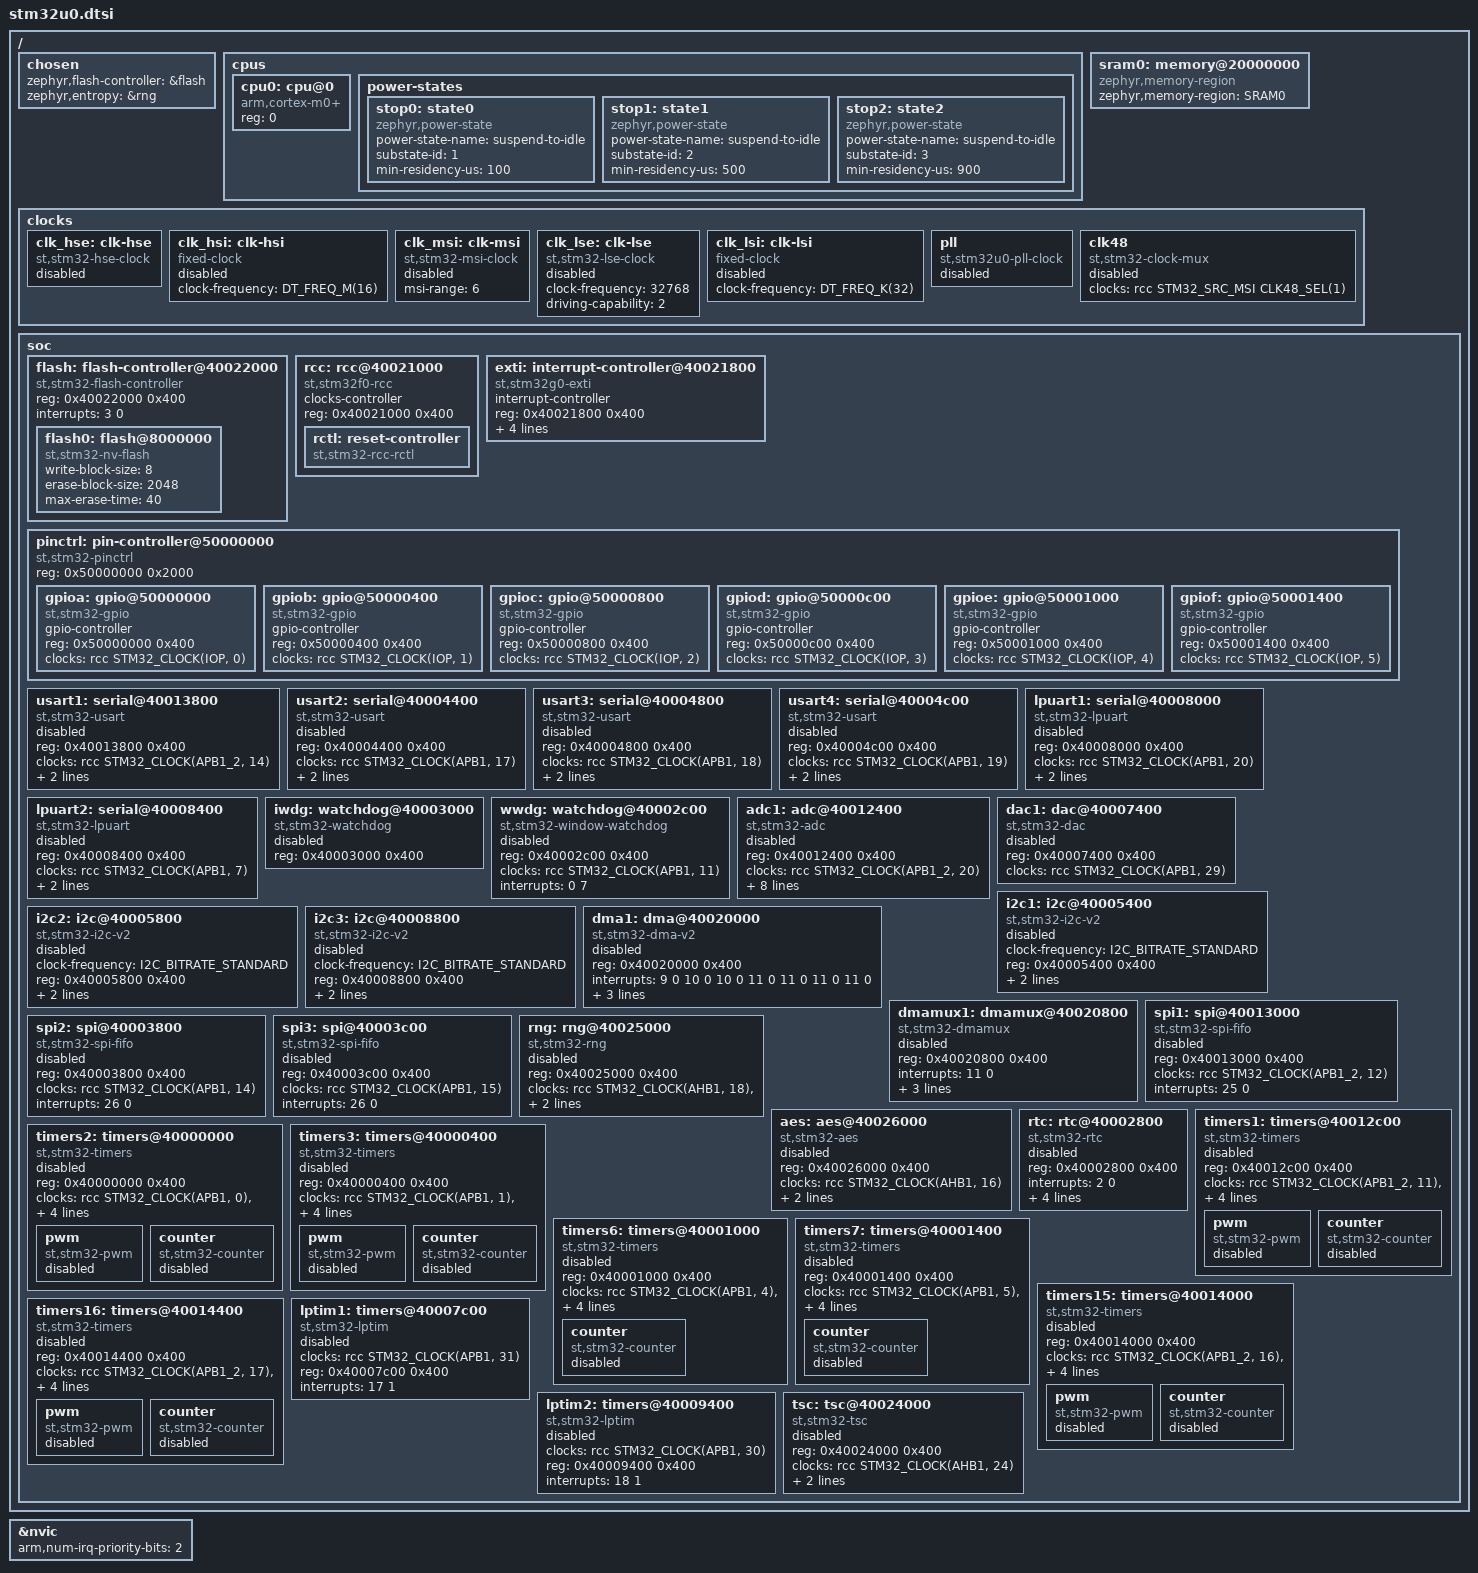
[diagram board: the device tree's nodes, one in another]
/*
 * Copyright (c) 2024 STMicroelectronics
 *
 * SPDX-License-Identifier: Apache-2.0
 */

#include <arm/armv6-m.dtsi>
#include <zephyr/dt-bindings/clock/stm32u0_clock.h>
#include <zephyr/dt-bindings/gpio/gpio.h>
#include <zephyr/dt-bindings/adc/adc.h>
#include <zephyr/dt-bindings/adc/stm32l4_adc.h>
#include <zephyr/dt-bindings/pwm/pwm.h>
#include <zephyr/dt-bindings/pwm/stm32_pwm.h>
#include <zephyr/dt-bindings/dma/stm32_dma.h>
#include <zephyr/dt-bindings/i2c/i2c.h>
#include <zephyr/dt-bindings/reset/stm32u0_reset.h>
#include <freq.h>
#include <mem.h>

/ {
	chosen {
		zephyr,flash-controller = &flash;
		zephyr,entropy = &rng;
	};

	cpus {
		#address-cells = <1>;
		#size-cells = <0>;

		cpu0: cpu@0 {
			device_type = "cpu";
			compatible = "arm,cortex-m0+";
			reg = <0>;
			#address-cells = <1>;
			#size-cells = <1>;
		};

		power-states {
			stop0: state0 {
				compatible = "zephyr,power-state";
				power-state-name = "suspend-to-idle";
				substate-id = <1>;
				min-residency-us = <100>;
			};

			stop1: state1 {
				compatible = "zephyr,power-state";
				power-state-name = "suspend-to-idle";
				substate-id = <2>;
				min-residency-us = <500>;
			};

			stop2: state2 {
				compatible = "zephyr,power-state";
				power-state-name = "suspend-to-idle";
				substate-id = <3>;
				min-residency-us = <900>;
			};
		};
	};

	sram0: memory@20000000 {
		compatible = "zephyr,memory-region", "mmio-sram";
		zephyr,memory-region = "SRAM0";
	};

	clocks {
		clk_hse: clk-hse {
			#clock-cells = <0>;
			compatible = "st,stm32-hse-clock";
			status = "disabled";
		};

		clk_hsi: clk-hsi {
			#clock-cells = <0>;
			compatible = "fixed-clock";
			clock-frequency = <DT_FREQ_M(16)>;
			status = "disabled";
		};

		clk_msi: clk-msi {
			#clock-cells = <0>;
			compatible = "st,stm32-msi-clock";
			msi-range = <6>; /* 4MHz (reset value) */
			status = "disabled";
		};

		clk_lse: clk-lse {
			#clock-cells = <0>;
			compatible = "st,stm32-lse-clock";
			clock-frequency = <32768>;
			driving-capability = <2>;
			status = "disabled";
		};

		clk_lsi: clk-lsi {
			#clock-cells = <0>;
			compatible = "fixed-clock";
			clock-frequency = <DT_FREQ_K(32)>;
			status = "disabled";
		};

		pll: pll {
			#clock-cells = <0>;
			compatible = "st,stm32u0-pll-clock";
			status = "disabled";
		};

		clk48: clk48 {
			#clock-cells = <0>;
			compatible = "st,stm32-clock-mux";
			clocks = <&rcc STM32_SRC_MSI CLK48_SEL(1)>;
			status = "disabled";
		};
	};

	soc {
		flash: flash-controller@40022000 {
			compatible = "st,stm32-flash-controller", "st,stm32g0-flash-controller";
			reg = <0x40022000 0x400>;
			interrupts = <3 0>;

			#address-cells = <1>;
			#size-cells = <1>;

			flash0: flash@8000000 {
				compatible = "st,stm32-nv-flash", "soc-nv-flash";

				write-block-size = <8>;
				erase-block-size = <2048>;
				/* maximum erase time(ms) for a 2K sector */
				max-erase-time = <40>;
			};
		};

		rcc: rcc@40021000 {
			compatible = "st,stm32f0-rcc";
			clocks-controller;
			#clock-cells = <2>;
			reg = <0x40021000 0x400>;

			rctl: reset-controller {
				compatible = "st,stm32-rcc-rctl";
				#reset-cells = <1>;
			};
		};

		exti: interrupt-controller@40021800 {
			compatible = "st,stm32g0-exti", "st,stm32-exti";
			interrupt-controller;
			#interrupt-cells = <1>;
			#address-cells = <0>;
			reg = <0x40021800 0x400>;
			clocks = <&rcc STM32_CLOCK(APB1_2, 0)>;
			num-lines = <32>;
			interrupts = <5 0>, <6 0>, <7 0>;
			interrupt-names = "line0-1", "line2-3", "line4-15";
			line-ranges = <0 2>, <2 2>, <4 12>;
		};

		pinctrl: pin-controller@50000000 {
			compatible = "st,stm32-pinctrl";
			#address-cells = <1>;
			#size-cells = <1>;
			reg = <0x50000000 0x2000>;

			gpioa: gpio@50000000 {
				compatible = "st,stm32-gpio";
				gpio-controller;
				#gpio-cells = <2>;
				reg = <0x50000000 0x400>;
				clocks = <&rcc STM32_CLOCK(IOP, 0)>;
			};

			gpiob: gpio@50000400 {
				compatible = "st,stm32-gpio";
				gpio-controller;
				#gpio-cells = <2>;
				reg = <0x50000400 0x400>;
				clocks = <&rcc STM32_CLOCK(IOP, 1)>;
			};

			gpioc: gpio@50000800 {
				compatible = "st,stm32-gpio";
				gpio-controller;
				#gpio-cells = <2>;
				reg = <0x50000800 0x400>;
				clocks = <&rcc STM32_CLOCK(IOP, 2)>;
			};

			gpiod: gpio@50000c00 {
				compatible = "st,stm32-gpio";
				gpio-controller;
				#gpio-cells = <2>;
				reg = <0x50000c00 0x400>;
				clocks = <&rcc STM32_CLOCK(IOP, 3)>;
			};

			gpioe: gpio@50001000 {
				compatible = "st,stm32-gpio";
				gpio-controller;
				#gpio-cells = <2>;
				reg = <0x50001000 0x400>;
				clocks = <&rcc STM32_CLOCK(IOP, 4)>;
			};

			gpiof: gpio@50001400 {
				compatible = "st,stm32-gpio";
				gpio-controller;
				#gpio-cells = <2>;
				reg = <0x50001400 0x400>;
				clocks = <&rcc STM32_CLOCK(IOP, 5)>;
			};
		};

		usart1: serial@40013800 {
			compatible = "st,stm32-usart", "st,stm32-uart";
			reg = <0x40013800 0x400>;
			clocks = <&rcc STM32_CLOCK(APB1_2, 14)>;
			resets = <&rctl STM32_RESET(APB1H, 14)>;
			interrupts = <27 0>;
			status = "disabled";
		};

		usart2: serial@40004400 {
			compatible = "st,stm32-usart", "st,stm32-uart";
			reg = <0x40004400 0x400>;
			clocks = <&rcc STM32_CLOCK(APB1, 17)>;
			resets = <&rctl STM32_RESET(APB1L, 17)>;
			interrupts = <28 0>;
			status = "disabled";
		};

		usart3: serial@40004800 {
			compatible = "st,stm32-usart", "st,stm32-uart";
			reg = <0x40004800 0x400>;
			clocks = <&rcc STM32_CLOCK(APB1, 18)>;
			resets = <&rctl STM32_RESET(APB1L, 18)>;
			interrupts = <29 0>;
			status = "disabled";
		};

		usart4: serial@40004c00 {
			compatible = "st,stm32-usart", "st,stm32-uart";
			reg = <0x40004c00 0x400>;
			clocks = <&rcc STM32_CLOCK(APB1, 19)>;
			resets = <&rctl STM32_RESET(APB1L, 19)>;
			interrupts = <30 0>;
			status = "disabled";
		};

		lpuart1: serial@40008000 {
			compatible = "st,stm32-lpuart", "st,stm32-uart";
			reg = <0x40008000 0x400>;
			clocks = <&rcc STM32_CLOCK(APB1, 20)>;
			resets = <&rctl STM32_RESET(APB1L, 20)>;
			interrupts = <29 0>;
			status = "disabled";
		};

		lpuart2: serial@40008400 {
			compatible = "st,stm32-lpuart", "st,stm32-uart";
			reg = <0x40008400 0x400>;
			clocks = <&rcc STM32_CLOCK(APB1, 7)>;
			resets = <&rctl STM32_RESET(APB1L, 7)>;
			interrupts = <28 0>;
			status = "disabled";
		};

		iwdg: watchdog@40003000 {
			compatible = "st,stm32-watchdog";
			reg = <0x40003000 0x400>;
			status = "disabled";
		};

		wwdg: watchdog@40002c00 {
			compatible = "st,stm32-window-watchdog";
			reg = <0x40002c00 0x400>;
			clocks = <&rcc STM32_CLOCK(APB1, 11)>;
			interrupts = <0 7>;
			status = "disabled";
		};

		adc1: adc@40012400 {
			compatible = "st,stm32-adc";
			reg = <0x40012400 0x400>;
			clocks = <&rcc STM32_CLOCK(APB1_2, 20)>;
			clock-names = "adcx";
			interrupts = <12 0>;
			#io-channel-cells = <1>;
			resolutions = <STM32_ADC_RES(12, 0x00)
				       STM32_ADC_RES(10, 0x01)
				       STM32_ADC_RES(8, 0x02)
				       STM32_ADC_RES(6, 0x03)>;
			sampling-times = <2 4 8 13 20 40 80 161>;
			num-sampling-time-common-channels = <2>;
			st,adc-sequencer = "fixed";
			st,adc-oversampler = "minimal";
			st,adc-internal-regulator = "startup-sw-delay";
			status = "disabled";
		};

		dac1: dac@40007400 {
			compatible = "st,stm32-dac";
			reg = <0x40007400 0x400>;
			clocks = <&rcc STM32_CLOCK(APB1, 29)>;
			status = "disabled";
			#io-channel-cells = <1>;
		};

		i2c1: i2c@40005400 {
			compatible = "st,stm32-i2c-v2";
			clock-frequency = <I2C_BITRATE_STANDARD>;
			#address-cells = <1>;
			#size-cells = <0>;
			reg = <0x40005400 0x400>;
			clocks = <&rcc STM32_CLOCK(APB1, 21)>;
			interrupts = <23 0>;
			interrupt-names = "combined";
			status = "disabled";
		};

		i2c2: i2c@40005800 {
			compatible = "st,stm32-i2c-v2";
			clock-frequency = <I2C_BITRATE_STANDARD>;
			#address-cells = <1>;
			#size-cells = <0>;
			reg = <0x40005800 0x400>;
			clocks = <&rcc STM32_CLOCK(APB1, 22)>;
			interrupts = <24 0>;
			interrupt-names = "combined";
			status = "disabled";
		};

		i2c3: i2c@40008800 {
			compatible = "st,stm32-i2c-v2";
			clock-frequency = <I2C_BITRATE_STANDARD>;
			#address-cells = <1>;
			#size-cells = <0>;
			reg = <0x40008800 0x400>;
			clocks = <&rcc STM32_CLOCK(APB1, 23)>;
			interrupts = <24 0>;
			interrupt-names = "combined";
			status = "disabled";
		};

		dma1: dma@40020000 {
			compatible = "st,stm32-dma-v2";
			#dma-cells = <3>;
			reg = <0x40020000 0x400>;
			interrupts = <9 0 10 0 10 0 11 0 11 0 11 0 11 0>;
			clocks = <&rcc STM32_CLOCK(AHB1, 0)>;
			dma-requests = <7>;
			dma-offset = <0>;
			status = "disabled";
		};

		dmamux1: dmamux@40020800 {
			compatible = "st,stm32-dmamux";
			#dma-cells = <3>;
			reg = <0x40020800 0x400>;
			interrupts = <11 0>;
			dma-channels = <7>;
			dma-generators = <4>;
			dma-requests = <76>;
			status = "disabled";
		};

		spi1: spi@40013000 {
			compatible = "st,stm32-spi-fifo", "st,stm32-spi";
			#address-cells = <1>;
			#size-cells = <0>;
			reg = <0x40013000 0x400>;
			clocks = <&rcc STM32_CLOCK(APB1_2, 12)>;
			interrupts = <25 0>;
			status = "disabled";
		};

		spi2: spi@40003800 {
			compatible = "st,stm32-spi-fifo", "st,stm32-spi";
			#address-cells = <1>;
			#size-cells = <0>;
			reg = <0x40003800 0x400>;
			clocks = <&rcc STM32_CLOCK(APB1, 14)>;
			interrupts = <26 0>;
			status = "disabled";
		};

		spi3: spi@40003c00 {
			compatible = "st,stm32-spi-fifo", "st,stm32-spi";
			#address-cells = <1>;
			#size-cells = <0>;
			reg = <0x40003c00 0x400>;
			clocks = <&rcc STM32_CLOCK(APB1, 15)>;
			interrupts = <26 0>;
			status = "disabled";
		};

		rng: rng@40025000 {
			compatible = "st,stm32-rng";
			reg = <0x40025000 0x400>;
			clocks = <&rcc STM32_CLOCK(AHB1, 18)>,
				 <&rcc STM32_SRC_CK48 NO_SEL>;
			interrupts = <31 0>;
			status = "disabled";
		};

		aes: aes@40026000 {
			compatible = "st,stm32-aes";
			reg = <0x40026000 0x400>;
			clocks = <&rcc STM32_CLOCK(AHB1, 16)>;
			resets = <&rctl STM32_RESET(AHB1, 16)>;
			interrupts = <31 0>;
			interrupt-names = "aes";
			status = "disabled";
		};

		rtc: rtc@40002800 {
			compatible = "st,stm32-rtc";
			reg = <0x40002800 0x400>;
			interrupts = <2 0>;
			clocks = <&rcc STM32_CLOCK(APB1, 10)>;
			prescaler = <32768>;
			alarms-count = <2>;
			alrm-exti-line = <28>;
			status = "disabled";
		};

		timers1: timers@40012c00 {
			compatible = "st,stm32-timers";
			reg = <0x40012c00 0x400>;
			clocks = <&rcc STM32_CLOCK(APB1_2, 11)>,
				 <&rcc STM32_SRC_PCLK TIM1_SEL(0)>;
			resets = <&rctl STM32_RESET(APB1H, 11)>;
			interrupts = <13 0>, <14 0>;
			interrupt-names = "brk_up_trg_com", "cc";
			st,prescaler = <0>;
			status = "disabled";

			pwm {
				compatible = "st,stm32-pwm";
				status = "disabled";
				#pwm-cells = <3>;
			};

			counter {
				compatible = "st,stm32-counter";
				status = "disabled";
			};
		};

		timers2: timers@40000000 {
			compatible = "st,stm32-timers";
			reg = <0x40000000 0x400>;
			clocks = <&rcc STM32_CLOCK(APB1, 0)>,
				 <&rcc STM32_SRC_PCLK NO_SEL>;
			resets = <&rctl STM32_RESET(APB1L, 0)>;
			interrupts = <15 0>;
			interrupt-names = "global";
			st,prescaler = <0>;
			status = "disabled";

			pwm {
				compatible = "st,stm32-pwm";
				status = "disabled";
				#pwm-cells = <3>;
			};

			counter {
				compatible = "st,stm32-counter";
				status = "disabled";
			};
		};

		timers3: timers@40000400 {
			compatible = "st,stm32-timers";
			reg = <0x40000400 0x400>;
			clocks = <&rcc STM32_CLOCK(APB1, 1)>,
				 <&rcc STM32_SRC_PCLK NO_SEL>;
			resets = <&rctl STM32_RESET(APB1L, 1)>;
			interrupts = <16 0>;
			interrupt-names = "global";
			st,prescaler = <0>;
			status = "disabled";

			pwm {
				compatible = "st,stm32-pwm";
				status = "disabled";
				#pwm-cells = <3>;
			};

			counter {
				compatible = "st,stm32-counter";
				status = "disabled";
			};
		};

		timers6: timers@40001000 {
			compatible = "st,stm32-timers";
			reg = <0x40001000 0x400>;
			clocks = <&rcc STM32_CLOCK(APB1, 4)>,
				 <&rcc STM32_SRC_PCLK NO_SEL>;
			resets = <&rctl STM32_RESET(APB1L, 4)>;
			interrupts = <17 0>;
			interrupt-names = "combined";
			st,prescaler = <0>;
			status = "disabled";

			counter {
				compatible = "st,stm32-counter";
				status = "disabled";
			};
		};

		timers7: timers@40001400 {
			compatible = "st,stm32-timers";
			reg = <0x40001400 0x400>;
			clocks = <&rcc STM32_CLOCK(APB1, 5)>,
				 <&rcc STM32_SRC_PCLK NO_SEL>;
			resets = <&rctl STM32_RESET(APB1L, 5)>;
			interrupts = <18 0>;
			interrupt-names = "combined";
			st,prescaler = <0>;
			status = "disabled";

			counter {
				compatible = "st,stm32-counter";
				status = "disabled";
			};
		};

		timers15: timers@40014000 {
			compatible = "st,stm32-timers";
			reg = <0x40014000 0x400>;
			clocks = <&rcc STM32_CLOCK(APB1_2, 16)>,
				 <&rcc STM32_SRC_PCLK TIM15_SEL(0)>;
			resets = <&rctl STM32_RESET(APB1H, 16)>;
			interrupts = <19 0>;
			interrupt-names = "combined";
			st,prescaler = <0>;
			status = "disabled";

			pwm {
				compatible = "st,stm32-pwm";
				status = "disabled";
				#pwm-cells = <3>;
			};

			counter {
				compatible = "st,stm32-counter";
				status = "disabled";
			};
		};

		timers16: timers@40014400 {
			compatible = "st,stm32-timers";
			reg = <0x40014400 0x400>;
			clocks = <&rcc STM32_CLOCK(APB1_2, 17)>,
				 <&rcc STM32_SRC_PCLK NO_SEL>;
			resets = <&rctl STM32_RESET(APB1H, 17)>;
			interrupts = <20 0>;
			interrupt-names = "global";
			st,prescaler = <0>;
			status = "disabled";

			pwm {
				compatible = "st,stm32-pwm";
				status = "disabled";
				#pwm-cells = <3>;
			};

			counter {
				compatible = "st,stm32-counter";
				status = "disabled";
			};
		};

		lptim1: timers@40007c00 {
			compatible = "st,stm32-lptim";
			clocks = <&rcc STM32_CLOCK(APB1, 31)>;
			#address-cells = <1>;
			#size-cells = <0>;
			reg = <0x40007c00 0x400>;
			interrupts = <17 1>;
			interrupt-names = "combined";
			status = "disabled";
		};

		lptim2: timers@40009400 {
			compatible = "st,stm32-lptim";
			clocks = <&rcc STM32_CLOCK(APB1, 30)>;
			#address-cells = <1>;
			#size-cells = <0>;
			reg = <0x40009400 0x400>;
			interrupts = <18 1>;
			interrupt-names = "combined";
			status = "disabled";
		};

		tsc: tsc@40024000 {
			compatible = "st,stm32-tsc";
			reg = <0x40024000 0x400>;
			clocks = <&rcc STM32_CLOCK(AHB1, 24)>;
			resets = <&rctl STM32_RESET(AHB1, 24)>;
			interrupts = <21 0>;
			interrupt-names = "global";
			status = "disabled";
		};
	};
};

&nvic {
	arm,num-irq-priority-bits = <2>;
};
